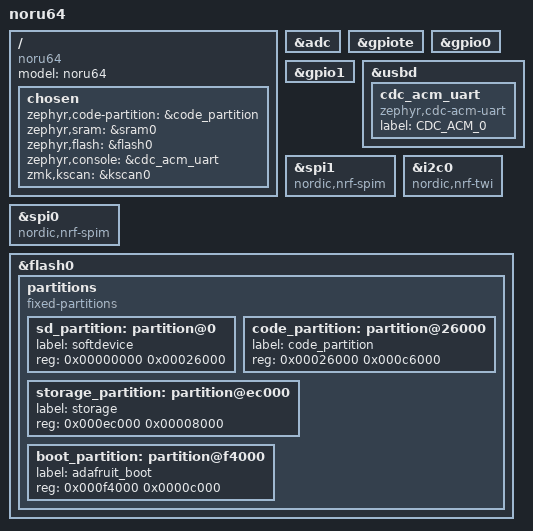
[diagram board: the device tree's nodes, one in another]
/*
 * Copyright (c) 2020 Eric Lau
 *
 * SPDX-License-Identifier: MIT
 */

/dts-v1/;
#include <nordic/nrf52840_qiaa.dtsi>
#include <dt-bindings/zmk/matrix_transform.h>
#include <dt-bindings/led/led.h>

/ {
	model = "noru64";
	compatible = "noru64";

	chosen {
		zephyr,code-partition = &code_partition;
		zephyr,sram = &sram0;
		zephyr,flash = &flash0;
		zephyr,console = &cdc_acm_uart;
		zmk,kscan = &kscan0;
	};
};

&adc {
	status = "okay";
};

&gpiote {
	status = "okay";
};

&gpio0 {
	status = "okay";
};

&gpio1 {
	status = "okay";
};

&usbd {
	status = "okay";
};

&spi1 {
	compatible = "nordic,nrf-spim";
};

&i2c0 {
 	compatible = "nordic,nrf-twi";
};


&spi0 {
	compatible = "nordic,nrf-spim";
};

&usbd {
	status = "okay";
	cdc_acm_uart: cdc_acm_uart {
		compatible = "zephyr,cdc-acm-uart";
		label = "CDC_ACM_0";
	};
};

&flash0 {
	/*
	 * For more information, see:
	 * http://docs.zephyrproject.org/latest/devices/dts/flash_partitions.html
	 */
	partitions {
		compatible = "fixed-partitions";
		#address-cells = <1>;
		#size-cells = <1>;

		sd_partition: partition@0 {
			label = "softdevice";
			reg = <0x00000000 0x00026000>;
		};
		code_partition: partition@26000 {
			label = "code_partition";
			reg = <0x00026000 0x000c6000>;
		};

		/*
		 * The flash starting at 0x000ec000 and ending at
		 * 0x000f3fff is reserved for use by the application.
		 */

		/*
		 * Storage partition will be used by FCB/LittleFS/NVS
		 * if enabled.
		 */
		storage_partition: partition@ec000 {
			label = "storage";
			reg = <0x000ec000 0x00008000>;
		};

		boot_partition: partition@f4000 {
			label = "adafruit_boot";
			reg = <0x000f4000 0x0000c000>;
		};
	};
};
